# LAN9255ZMX019 register map
Vendor: Microchip
Registers are 32-bit, read-write, reset 0x0 unless marked. A register's access mark holds for its fields unless they carry their own. Addresses are absolute, and some are shared; only a register's first bit layout is shown; [hi:lo] are bit positions; 'fields as' and 'values as' point back to an identical list.

## PDEC
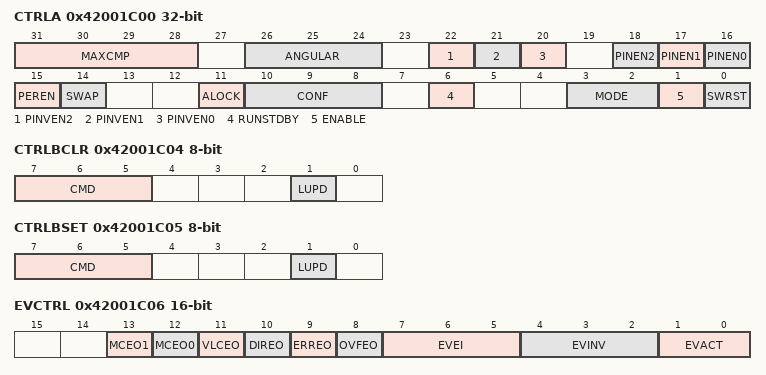
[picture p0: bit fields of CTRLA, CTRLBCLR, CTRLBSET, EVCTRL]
0x42001C00 CTRLA
  [31:28] MAXCMP — Maximum Consecutive Missing Pulses
  [26:24] ANGULAR — Angular Counter Length
  [22] PINVEN2 — IO Pin 2 Invert Enable
  [21] PINVEN1 — IO Pin 1 Invert Enable
  [20] PINVEN0 — IO Pin 0 Invert Enable
  [18] PINEN2 — PDEC Input From Pin 2 Enable
  [17] PINEN1 — PDEC Input From Pin 1 Enable
  [16] PINEN0 — PDEC Input From Pin 0 Enable
  [15] PEREN — Period Enable
  [14] SWAP — PDEC Phase A and B Swap
  [11] ALOCK — Auto Lock
  [10:8] CONF — PDEC Configuration
    0=X4 (Quadrature decoder direction); 1=X4S (Secure Quadrature decoder direction); 2=X2 (Decoder direction); 3=X2S (Secure decoder direction); 4=AUTOC (Auto correction mode)
  [6] RUNSTDBY — Run in Standby
  [3:2] MODE — Operation Mode
    0=QDEC (QDEC operating mode); 1=HALL (HALL operating mode); 2=COUNTER (COUNTER operating mode)
  [1] ENABLE
  [0] SWRST — Software Reset
0x42001C04 CTRLBCLR 8-bit
  [7:5] CMD — Command
    0=NONE (No action); 1=RETRIGGER (Force a counter restart or retrigger); 2=UPDATE (Force update of double buffered registers); 3=READSYNC (Force a read synchronization of COUNT); 4=START (Start QDEC/HALL); 5=STOP (Stop QDEC/HALL)
  [1] LUPD — Lock Update
0x42001C05 CTRLBSET 8-bit
  fields as CTRLBCLR
0x42001C06 EVCTRL 16-bit
  [13] MCEO1 — Match Channel 1 Event Output Enable
  [12] MCEO0 — Match Channel 0 Event Output Enable
  [11] VLCEO — Velocity Output Event Enable
  [10] DIREO — Direction Output Event Enable
  [9] ERREO — Error Output Event Enable
  [8] OVFEO — Overflow/Underflow Output Event Enable
  [7:5] EVEI — Event Input Enable
  [4:2] EVINV — Inverted Event Input Enable
  [1:0] EVACT — Event Action
    0=OFF (Event action disabled); 1=RETRIGGER (Start, restart or retrigger on event); 2=COUNT (Count on event)
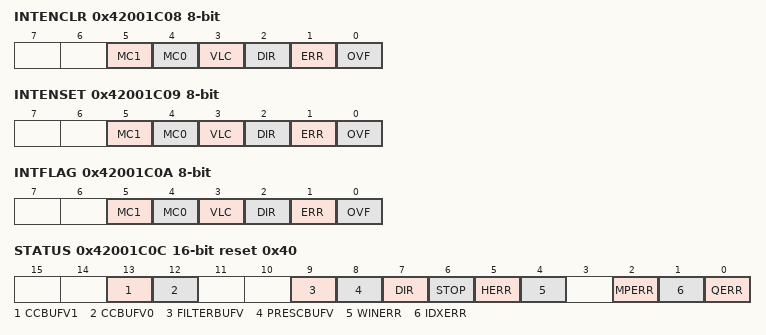
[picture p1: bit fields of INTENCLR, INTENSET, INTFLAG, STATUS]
0x42001C08 INTENCLR 8-bit
  [5] MC1 — Channel 1 Compare Match Disable
  [4] MC0 — Channel 0 Compare Match Disable
  [3] VLC — Velocity Interrupt Disable
  [2] DIR — Direction Interrupt Disable
  [1] ERR — Error Interrupt Disable
  [0] OVF — Overflow/Underflow Interrupt Disable
0x42001C09 INTENSET 8-bit
  [5] MC1 — Channel 1 Compare Match Enable
  [4] MC0 — Channel 0 Compare Match Enable
  [3] VLC — Velocity Interrupt Enable
  [2] DIR — Direction Interrupt Enable
  [1] ERR — Error Interrupt Enable
  [0] OVF — Overflow/Underflow Interrupt Enable
0x42001C0A INTFLAG 8-bit
  [5] MC1 — Channel 1 Compare Match
  [4] MC0 — Channel 0 Compare Match
  [3] VLC — Velocity
  [2] DIR — Direction Change
  [1] ERR — Error
  [0] OVF — Overflow/Underflow
0x42001C0C STATUS 16-bit reset 0x40
  [13] CCBUFV1 — Compare Channel 1 Buffer Valid
  [12] CCBUFV0 — Compare Channel 0 Buffer Valid
  [9] FILTERBUFV — Filter Buffer Valid
  [8] PRESCBUFV — Prescaler Buffer Valid
  [7] DIR — Direction Status Flag
  [6] STOP
  [5] HERR — Hall Error Flag
  [4] WINERR — Window Error Flag
  [2] MPERR — Missing Pulse Error flag
  [1] IDXERR — Index Error Flag
  [0] QERR — Quadrature Error Flag
0x42001C0F DBGCTRL 8-bit
  [0] DBGRUN — Debug Run Mode
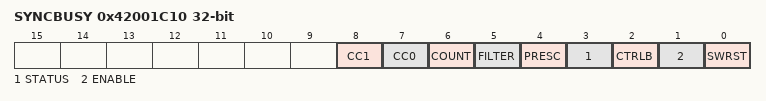
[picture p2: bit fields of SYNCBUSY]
0x42001C10 SYNCBUSY ro
  [8] CC1 — Compare Channel 1 Synchronization Busy
  [7] CC0 — Compare Channel 0 Synchronization Busy
  [6] COUNT — Count Synchronization Busy
  [5] FILTER — Filter Synchronization Busy
  [4] PRESC — Prescaler Synchronization Busy
  [3] STATUS — Status Synchronization Busy
  [2] CTRLB — Control B Synchronization Busy
  [1] ENABLE — Enable Synchronization Busy
  [0] SWRST — Software Reset Synchronization Busy
0x42001C14 PRESC 8-bit
  [3:0] PRESC — Prescaler Value
    0=DIV1 (No division); 1=DIV2 (Divide by 2); 2=DIV4 (Divide by 4); 3=DIV8 (Divide by 8); 4=DIV16 (Divide by 16); 5=DIV32 (Divide by 32); 6=DIV64 (Divide by 64); 7=DIV128 (Divide by 128); 8=DIV256 (Divide by 256); 9=DIV512 (Divide by 512); 10=DIV1024 (Divide by 1024)
0x42001C15 FILTER 8-bit
  [7:0] FILTER — Filter Value
0x42001C18 PRESCBUF 8-bit
  [3:0] PRESCBUF — Prescaler Buffer Value
    values as PRESC.PRESC
0x42001C19 FILTERBUF 8-bit
  [7:0] FILTERBUF — Filter Buffer Value
0x42001C1C COUNT
  [15:0] COUNT — Counter Value
0x42001C20 CC0
  [15:0] CC — Channel Compare Value
0x42001C24 CC1
  [15:0] CC — Channel Compare Value
0x42001C30 CCBUF0
  [15:0] CCBUF — Channel Compare Buffer Value
0x42001C34 CCBUF1
  [15:0] CCBUF — Channel Compare Buffer Value
